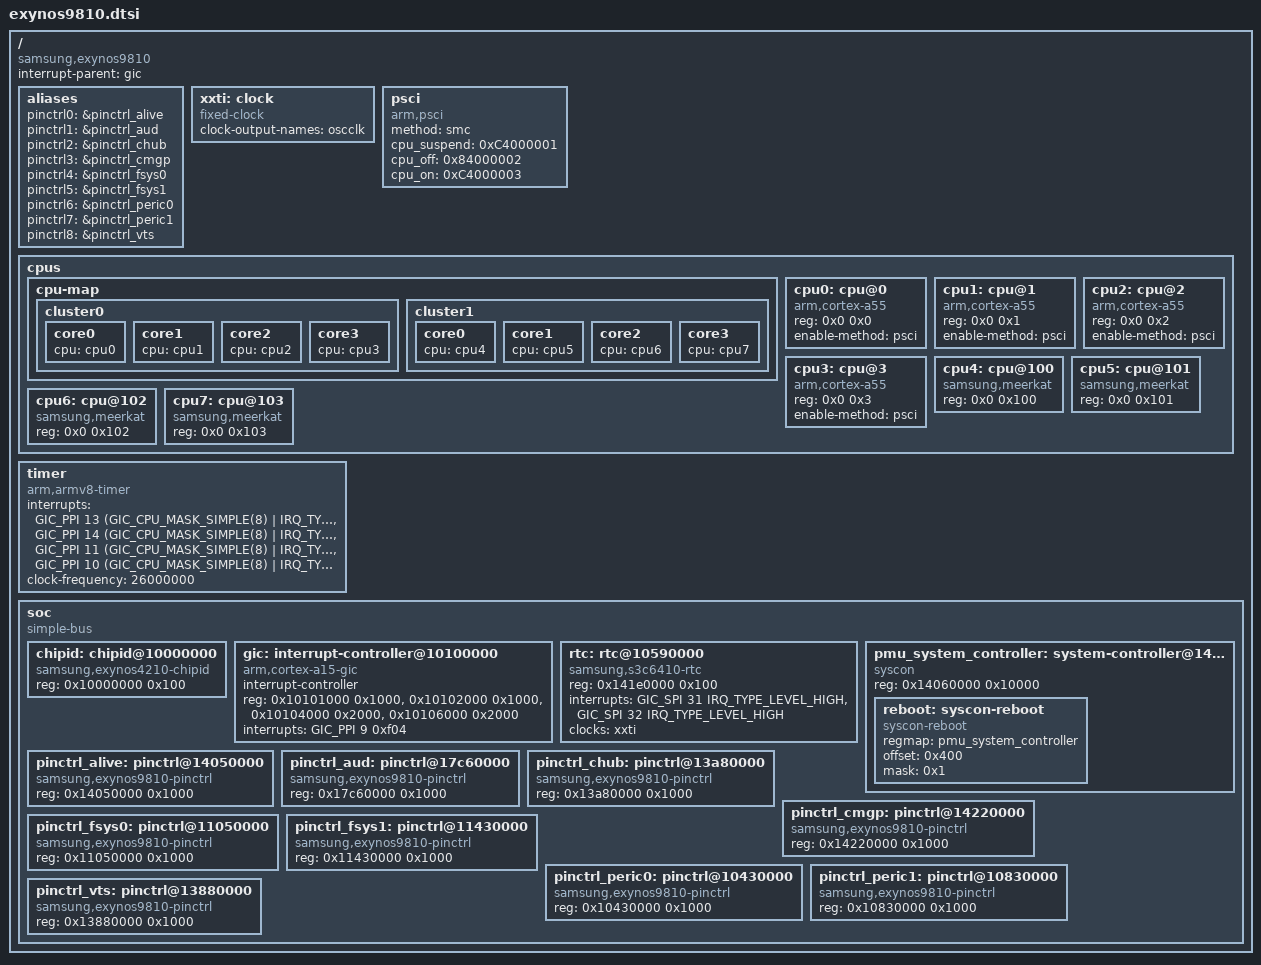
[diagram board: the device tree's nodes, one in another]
// SPDX-License-Identifier: GPL-2.0
/*
 * Samsung Exynos9810 SoC device tree source
 *
 * Samsung Exynos9810 SoC device nodes are listed in this file.
 * Exynos9810 based board files can include this file and provide
 * values for board specific bindings.
*/

#include <dt-bindings/interrupt-controller/arm-gic.h>

/ {
	compatible = "samsung,exynos9810";
	#address-cells = <2>;
	#size-cells = <2>;

	interrupt-parent = <&gic>;

	aliases {
		pinctrl0 = &pinctrl_alive;
		pinctrl1 = &pinctrl_aud;
		pinctrl2 = &pinctrl_chub;
		pinctrl3 = &pinctrl_cmgp;
		pinctrl4 = &pinctrl_fsys0;
		pinctrl5 = &pinctrl_fsys1;
		pinctrl6 = &pinctrl_peric0;
		pinctrl7 = &pinctrl_peric1;
		pinctrl8 = &pinctrl_vts;
	};

	xxti: clock {
		compatible = "fixed-clock";
		clock-output-names = "oscclk";
		#clock-cells = <0>;
	};

	psci {
		compatible = "arm,psci";
		method = "smc";
		cpu_suspend = <0xC4000001>;
		cpu_off = <0x84000002>;
		cpu_on = <0xC4000003>;
	};

	cpus {
		#address-cells = <2>;
		#size-cells = <0>;

		cpu-map {
			cluster0 {
				core0 {
					cpu = <&cpu0>;
				};
				core1 {
					cpu = <&cpu1>;
				};
				core2 {
					cpu = <&cpu2>;
				};
				core3 {
					cpu = <&cpu3>;
				};
			};

			cluster1 {
				core0 {
					cpu = <&cpu4>;
				};
				core1 {
					cpu = <&cpu5>;
				};
				core2 {
					cpu = <&cpu6>;
				};
				core3 {
					cpu = <&cpu7>;
				};
			};
		};

		cpu0: cpu@0 {
			device_type = "cpu";
			compatible = "arm,cortex-a55", "arm,armv8";
			reg = <0x0 0x0>;
			enable-method = "psci";
		};
		cpu1: cpu@1 {
			device_type = "cpu";
			compatible = "arm,cortex-a55", "arm,armv8";
			reg = <0x0 0x1>;
			enable-method = "psci";
		};
		cpu2: cpu@2 {
			device_type = "cpu";
			compatible = "arm,cortex-a55", "arm,armv8";
			reg = <0x0 0x2>;
			enable-method = "psci";
		};
		cpu3: cpu@3 {
			device_type = "cpu";
			compatible = "arm,cortex-a55", "arm,armv8";
			reg = <0x0 0x3>;
			enable-method = "psci";
		};
		cpu4: cpu@100 {
			device_type = "cpu";
			compatible = "samsung,meerkat", "arm,armv8";
			reg = <0x0 0x100>;
		};
		cpu5: cpu@101 {
			device_type = "cpu";
			compatible = "samsung,meerkat", "arm,armv8";
			reg = <0x0 0x101>;
		};
		cpu6: cpu@102 {
			device_type = "cpu";
			compatible = "samsung,meerkat", "arm,armv8";
			reg = <0x0 0x102>;
		};
		cpu7: cpu@103 {
			device_type = "cpu";
			compatible = "samsung,meerkat", "arm,armv8";
			reg = <0x0 0x103>;
		};
	};

    	timer: timer {
		compatible = "arm,armv8-timer";
		interrupts = <GIC_PPI 13
			(GIC_CPU_MASK_SIMPLE(8) | IRQ_TYPE_LEVEL_LOW)>,
		<GIC_PPI 14
			(GIC_CPU_MASK_SIMPLE(8) | IRQ_TYPE_LEVEL_LOW)>,
		<GIC_PPI 11
			(GIC_CPU_MASK_SIMPLE(8) | IRQ_TYPE_LEVEL_LOW)>,
		<GIC_PPI 10
			(GIC_CPU_MASK_SIMPLE(8) | IRQ_TYPE_LEVEL_LOW)>;
		clock-frequency = <26000000>;
	};

	soc: soc {
		compatible = "simple-bus";
		#address-cells = <1>;
		#size-cells = <1>;
		ranges = <0 0 0 0x18000000>;

		chipid: chipid@10000000 {
			compatible = "samsung,exynos4210-chipid";
			reg = <0x10000000 0x100>;
		};

		gic: interrupt-controller@10100000 {
			compatible = "arm,cortex-a15-gic";
			#interrupt-cells = <3>;
			interrupt-controller;
			reg = <0x10101000 0x1000>,
			      <0x10102000 0x1000>,
			      <0x10104000 0x2000>,
			      <0x10106000 0x2000>;
			interrupts = <GIC_PPI 9 0xf04>;
		};

		rtc: rtc@10590000 {
			compatible = "samsung,s3c6410-rtc";
			reg = <0x141e0000 0x100>;
			interrupts = <GIC_SPI 31 IRQ_TYPE_LEVEL_HIGH>,
				     <GIC_SPI 32 IRQ_TYPE_LEVEL_HIGH>;
			clocks = <&xxti>;
			clock-names = "rtc";
		};
	
		pmu_system_controller: system-controller@14060000 {
			compatible = "syscon";
			reg = <0x14060000 0x10000>;

			reboot: syscon-reboot {
				compatible = "syscon-reboot";
				regmap = <&pmu_system_controller>;
				offset = <0x400>; /* SWRESET */
				mask = <0x1>;
			};
		};

		pinctrl_alive: pinctrl@14050000 {
			compatible = "samsung,exynos9810-pinctrl";
			reg = <0x14050000 0x1000>;
		};

		pinctrl_aud: pinctrl@17c60000 {
			compatible = "samsung,exynos9810-pinctrl";
			reg = <0x17c60000 0x1000>;
		};

		pinctrl_chub: pinctrl@13a80000 {
			compatible = "samsung,exynos9810-pinctrl";
			reg = <0x13a80000 0x1000>;
		};

		pinctrl_cmgp: pinctrl@14220000 {
			compatible = "samsung,exynos9810-pinctrl";
			reg = <0x14220000 0x1000>;
		};

		pinctrl_fsys0: pinctrl@11050000 {
			compatible = "samsung,exynos9810-pinctrl";
			reg = <0x11050000 0x1000>;
		};

		pinctrl_fsys1: pinctrl@11430000 {
			compatible = "samsung,exynos9810-pinctrl";
			reg = <0x11430000 0x1000>;
		};

		pinctrl_peric0: pinctrl@10430000 {
			compatible = "samsung,exynos9810-pinctrl";
			reg = <0x10430000 0x1000>;
		};

		pinctrl_peric1: pinctrl@10830000 {
			compatible = "samsung,exynos9810-pinctrl";
			reg = <0x10830000 0x1000>;
		};

		pinctrl_vts: pinctrl@13880000 {
			compatible = "samsung,exynos9810-pinctrl";
			reg = <0x13880000 0x1000>;
		};
	};
};

#include "exynos9810-pinctrl.dtsi"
